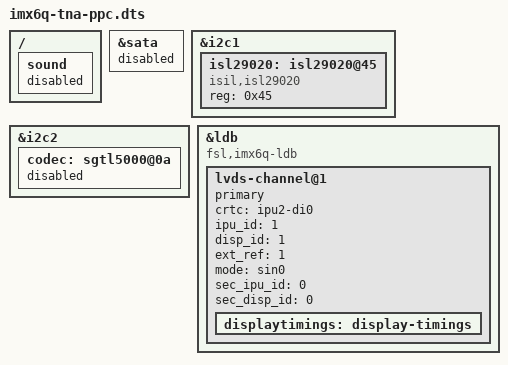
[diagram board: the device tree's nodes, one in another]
/*
 * Copyright 2018 Data Modul AG, Reyhaneh Yazdani <reyhane.y84@gmail.com>
 *
 * The code contained herein is licensed under the GNU General Public
 * License. You may obtain a copy of the GNU General Public License
 * Version 2 or later at the following locations:
 *
 * http://www.opensource.org/licenses/gpl-license.html
 * http://www.gnu.org/copyleft/gpl.html
 */

#include "imx6q-dmo-ppc.dts"

/ {
	sound {
		status = "disabled";
	};
};

&sata {
	status = "disabled";
};

&i2c1 {
	isl29020: isl29020@45 {
		compatible = "isil,isl29020";
		reg = <0x45>;
	};
};

&i2c2 {
	codec: sgtl5000@0a {
		status = "disabled";
	};
};

&ldb {
	compatible = "fsl,imx6q-ldb";
	status = "okay";
	
	lvds-channel@1 {
		primary;
		crtc = "ipu2-di0";
		ipu_id = <1>;
		disp_id = <1>;
		ext_ref = <1>;
		mode = "sin0";
		sec_ipu_id = <0>;
		sec_disp_id = <0>;
		status = "okay";
		displaytimings: display-timings {};
	};
};

#include "displaytiming-chimei-g101ICE.dts"
